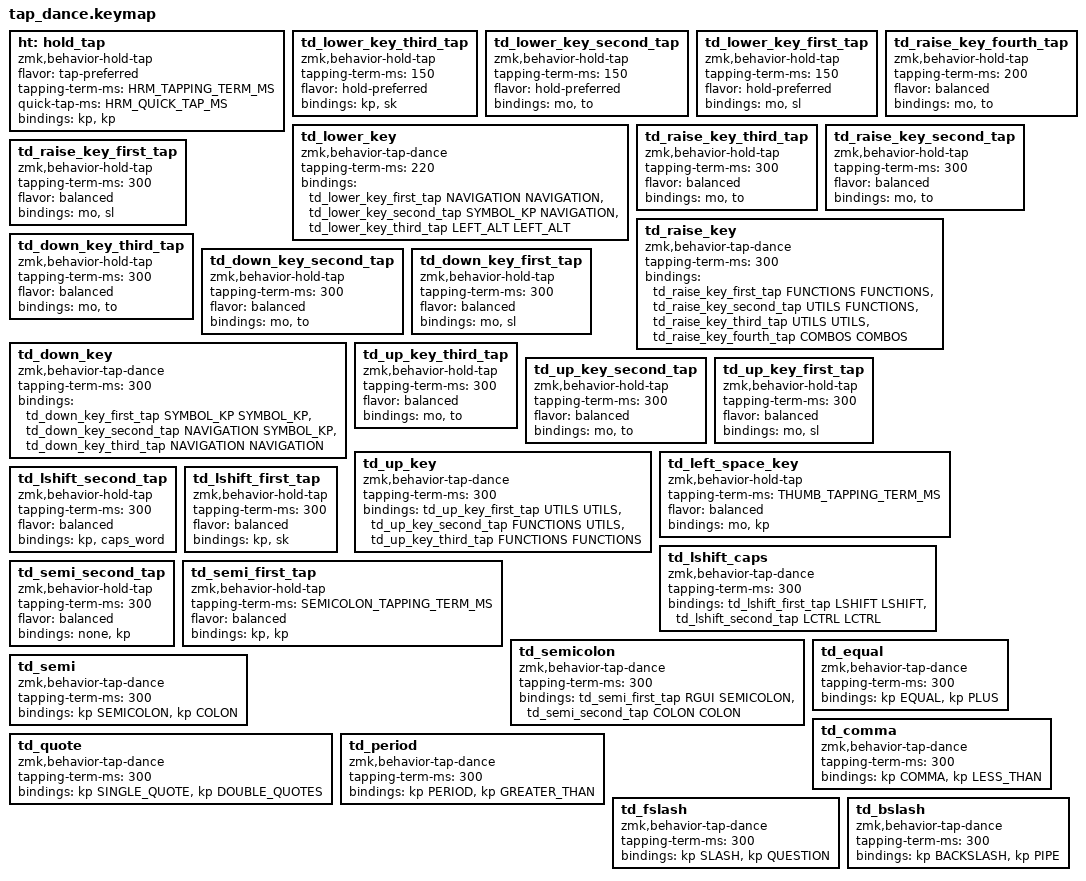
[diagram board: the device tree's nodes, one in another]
ht: hold_tap {
  // label = "hold_tap";
  compatible = "zmk,behavior-hold-tap";
  #binding-cells = <2>;
  flavor = "tap-preferred";
  tapping-term-ms = <HRM_TAPPING_TERM_MS>;
  quick-tap-ms = <HRM_QUICK_TAP_MS>;
  bindings = <&kp>, <&kp>;
};

//=======================================================================

// Lower key:
// Hold = Temporary Lower layer, then released when Lower layer is released
// Tap  = sticky Lower is active, then after next key press Lower is released
// Double Tap = Activate Lower layer
// Double Hold = nothing
// Triple Tap = Left Alt is sticky, then after next key press Left Alt is released
// Triple Hold = Left Alt is active while held, then released when Lower layer is released

td_lower_key_third_tap: td_lower_key_third_tap {
    compatible = "zmk,behavior-hold-tap";
    #binding-cells = <2>;
    tapping-term-ms = <150>;
    flavor = "hold-preferred";
    bindings = <&kp>, <&sk>; // 2xtap-then-hold = LALT hold, 3xtap = LALT sticky key
};
td_lower_key_second_tap: td_lower_key_second_tap {
    compatible = "zmk,behavior-hold-tap";
    #binding-cells = <2>;
    tapping-term-ms = <150>;
    flavor = "hold-preferred";
    bindings = <&mo>, <&to>; // tap-then-hold = layer SYMBOL_KP hold, 2xtap = activate layer NAV
};
td_lower_key_first_tap: td_lower_key_first_tap {
    compatible = "zmk,behavior-hold-tap";
    #binding-cells = <2>;
    tapping-term-ms = <150>;
    flavor = "hold-preferred";
    bindings = <&mo>, <&sl>; // hold = layer NAVIGATION until release, 1xtap = sticky layer NAV
};

td_lower_key: td_lower_key {
  compatible = "zmk,behavior-tap-dance";
  #binding-cells = <0>;
  tapping-term-ms = <220>;
  bindings = <&td_lower_key_first_tap NAVIGATION NAVIGATION>, <&td_lower_key_second_tap SYMBOL_KP NAVIGATION>, <&td_lower_key_third_tap LEFT_ALT LEFT_ALT>;
};

//=======================================================================

// Raise key:
// Hold = Temporary Raise layer, then released when Raise layer is released
// Tap  = sticky Raise is active, then after next key press Raise is released
// Double Tap = Activate Raise layer
// Double Hold = Layer KP_SYMBOLS is active while held, then released when Raise key is released
// Triple Tap = Activate Utils layer
// Triple Hold = Layer Utils is active while held, then released when Raise key is released

td_raise_key_fourth_tap: td_raise_key_fourth_tap {
    compatible = "zmk,behavior-hold-tap";
    #binding-cells = <2>;
    tapping-term-ms = <200>;
    flavor = "balanced";
    bindings = <&mo>, <&to>; // 2xtap-then-hold = COMBOS layer hold, 3xtap = activate layer COMBOS
};

td_raise_key_third_tap: td_raise_key_third_tap {
    compatible = "zmk,behavior-hold-tap";
    #binding-cells = <2>;
    tapping-term-ms = <300>;
    flavor = "balanced";
    bindings = <&mo>, <&to>; // 2xtap-then-hold = Utils layer hold, 3xtap = activate layer Utils
};
td_raise_key_second_tap: td_raise_key_second_tap {
    compatible = "zmk,behavior-hold-tap";
    #binding-cells = <2>;
    tapping-term-ms = <300>;
    flavor = "balanced";
    bindings = <&mo>, <&to>; // tap-then-hold = layer UTILS hold, 2xtap = activate layer FUNCTIONS
};
td_raise_key_first_tap: td_raise_key_first_tap {
    compatible = "zmk,behavior-hold-tap";
    #binding-cells = <2>;
    tapping-term-ms = <300>;
    flavor = "balanced";
    bindings = <&mo>, <&sl>; // hold = layer FUNCTIONS until release, 1xtap = sticky layer KP_SYMBOLS
};

td_raise_key: td_raise_key {
  compatible = "zmk,behavior-tap-dance";
  #binding-cells = <0>;
  tapping-term-ms = <300>;
  bindings = <&td_raise_key_first_tap FUNCTIONS FUNCTIONS>, <&td_raise_key_second_tap UTILS FUNCTIONS>, <&td_raise_key_third_tap UTILS UTILS>, <&td_raise_key_fourth_tap COMBOS COMBOS>;
};

//=======================================================================

// Down key:
// Hold = Temporary Down layer, then released when Down layer is released
// Tap  = sticky Down is active, then after next key press Down is released
// Double Tap = Activate Down layer
// Double Hold = Layer NAV is active while held, then released when Raise key is released
// Triple Tap = Activate Navigate layer
// Triple Hold = Layer Navigate is active while held, then released when Raise key is released

td_down_key_third_tap: td_down_key_third_tap {
    compatible = "zmk,behavior-hold-tap";
    #binding-cells = <2>;
    tapping-term-ms = <300>;
    flavor = "balanced";
    bindings = <&mo>, <&to>; // 2xtap-then-hold = NAV layer hold, 3xtap = activate NAV
};
td_down_key_second_tap: td_down_key_second_tap {
    compatible = "zmk,behavior-hold-tap";
    #binding-cells = <2>;
    tapping-term-ms = <300>;
    flavor = "balanced";
    bindings = <&mo>, <&to>; // tap-then-hold = layer NAVIGATION hold, 2xtap = activate layer SYMBOL_KP
};
td_down_key_first_tap: td_down_key_first_tap {
    compatible = "zmk,behavior-hold-tap";
    #binding-cells = <2>;
    tapping-term-ms = <300>;
    flavor = "balanced";
    bindings = <&mo>, <&sl>; // hold = layer FUNCTIONS until release, 1xtap = sticky layer SYMBOL_KP
};

td_down_key: td_down_key {
  compatible = "zmk,behavior-tap-dance";
  #binding-cells = <0>;
  tapping-term-ms = <300>;
  bindings = <&td_down_key_first_tap SYMBOL_KP SYMBOL_KP>, <&td_down_key_second_tap NAVIGATION SYMBOL_KP>, <&td_down_key_third_tap NAVIGATION NAVIGATION>;
};

//=======================================================================

// Up key:
// Hold = Temporary Up layer, then released when Up layer is released
// Tap  = sticky Up is active, then after next key press Up is released
// Double Tap = Activate Up layer
// Double Hold = Layer KP_SYMBOLS is active while held, then released when Raise key is released
// Triple Tap = Activate Functions layer
// Triple Hold = Layer Functions is active while held, then released when Raise key is released

td_up_key_third_tap: td_up_key_third_tap {
    compatible = "zmk,behavior-hold-tap";
    #binding-cells = <2>;
    tapping-term-ms = <300>;
    flavor = "balanced";
    bindings = <&mo>, <&to>; // 2xtap-then-hold = FUNCTIONS layer hold, 3xtap = activate FUNCTIONS
};
td_up_key_second_tap: td_up_key_second_tap {
    compatible = "zmk,behavior-hold-tap";
    #binding-cells = <2>;
    tapping-term-ms = <300>;
    flavor = "balanced";
    bindings = <&mo>, <&to>; // tap-then-hold = layer FUNCTIONS hold, 2xtap = activate layer UTILS
};
td_up_key_first_tap: td_up_key_first_tap {
    compatible = "zmk,behavior-hold-tap";
    #binding-cells = <2>;
    tapping-term-ms = <300>;
    flavor = "balanced";
    bindings = <&mo>, <&sl>; // hold = layer UTILS until release, 1xtap = sticky layer UTILS
};

td_up_key: td_up_key {
  compatible = "zmk,behavior-tap-dance";
  #binding-cells = <0>;
  tapping-term-ms = <300>;
  bindings = <&td_up_key_first_tap UTILS UTILS>, <&td_up_key_second_tap FUNCTIONS UTILS>, <&td_up_key_third_tap FUNCTIONS FUNCTIONS>;
};

//=======================================================================



td_left_space_key: td_left_space_key {
  compatible = "zmk,behavior-hold-tap";
  #binding-cells = <2>;
  tapping-term-ms = <THUMB_TAPPING_TERM_MS>;
  flavor = "balanced";
  bindings = <&mo>, <&kp>;
};

//=======================================================================

// Left Shift:
// Hold = Temporary Left Shift, then released when Shift key is released
// Tap  = sticky Shift is active, then after next key press Shift is released
// Double Tap = Caps Word is enabled
// Double Hold = While held down LEFT CONTROL is active until released

td_lshift_second_tap: td_lshift_second_tap {
    compatible = "zmk,behavior-hold-tap";
    #binding-cells = <2>;
    tapping-term-ms = <300>;
    flavor = "balanced";
    bindings = <&kp>, <&caps_word>; // tap-then-hold, 2xtap
};
td_lshift_first_tap: td_lshift_first_tap {
    compatible = "zmk,behavior-hold-tap";
    #binding-cells = <2>;
    tapping-term-ms = <300>;
    flavor = "balanced";
    bindings = <&kp>, <&sk>; // hold, 1xtap
};

td_lshift_caps: td_lshift_caps {
  compatible = "zmk,behavior-tap-dance";
  #binding-cells = <0>;
  tapping-term-ms = <300>;
  bindings = <&td_lshift_first_tap LSHIFT LSHIFT>, <&td_lshift_second_tap LCTRL LCTRL>;
};


///=======================================================================

// Left Semicolon
// Hold = Right GUI
// Tap  = Semicolon (;)
// Double Tap = Colon (:)
// Double Hold = nothing

td_semi_second_tap: td_semi_second_tap {
    compatible = "zmk,behavior-hold-tap";
    #binding-cells = <2>;
    tapping-term-ms = <300>;
    flavor = "balanced";
    bindings = <&none>, <&kp>; // tap-then-hold, 2xtap
};
td_semi_first_tap: td_semi_first_tap {
    compatible = "zmk,behavior-hold-tap";
    #binding-cells = <2>;
    tapping-term-ms = <SEMICOLON_TAPPING_TERM_MS>;
    flavor = "balanced";
    bindings = <&kp>, <&kp>; // hold, 1xtap
};

td_semicolon: td_semicolon {
  compatible = "zmk,behavior-tap-dance";
  #binding-cells = <0>;
  tapping-term-ms = <300>;
  bindings = <&td_semi_first_tap RGUI SEMICOLON>, <&td_semi_second_tap COLON COLON>;
};


//=======================================================================


td_equal: td_equal {
  compatible = "zmk,behavior-tap-dance";
  // label = "TAP_DANCE_EQUAL";
  #binding-cells = <0>;
  tapping-term-ms = <300>;
  bindings = <&kp EQUAL>, <&kp PLUS>;
};

td_semi: td_semi {
  compatible = "zmk,behavior-tap-dance";
  // label = "TAP_DANCE_SEMI";
  #binding-cells = <0>;
  tapping-term-ms = <300>;
  bindings = <&kp SEMICOLON>, <&kp COLON>;
};

td_quote: td_quote {
  compatible = "zmk,behavior-tap-dance";
  // label = "TAP_DANCE_QUOTE";
  #binding-cells = <0>;
  tapping-term-ms = <300>;
  bindings = <&kp SINGLE_QUOTE>, <&kp DOUBLE_QUOTES>;
};

td_comma: td_comma {
  compatible = "zmk,behavior-tap-dance";
  // label = "TAP_DANCE_COMMA";
  #binding-cells = <0>;
  tapping-term-ms = <300>;
  bindings = <&kp COMMA>, <&kp LESS_THAN>;
};

td_period: td_period {
  compatible = "zmk,behavior-tap-dance";
  // label = "TAP_DANCE_PERIOD";
  #binding-cells = <0>;
  tapping-term-ms = <300>;
  bindings = <&kp PERIOD>, <&kp GREATER_THAN>;
};

td_fslash: td_fslash {
  compatible = "zmk,behavior-tap-dance";
  // label = "TAP_DANCE_FSLASH";
  #binding-cells = <0>;
  tapping-term-ms = <300>;
  bindings = <&kp SLASH>, <&kp QUESTION>;
};

td_bslash: td_bslash {
  compatible = "zmk,behavior-tap-dance";
  // label = "TAP_DANCE_BSLASH";
  #binding-cells = <0>;
  tapping-term-ms = <300>;
  bindings = <&kp BACKSLASH>, <&kp PIPE>;
};

//=======================================================================

// td_alt: tab_dance_alt {
//         label = "TAP_DANCE_ALT";
//         compatible = "zmk,behavior-tap-dance";
//         #binding-cells = <0>;
//         tapping-term-ms = <200>;
//         bindings = <&kp LALT>, <&mo NUMBER>;
// };

